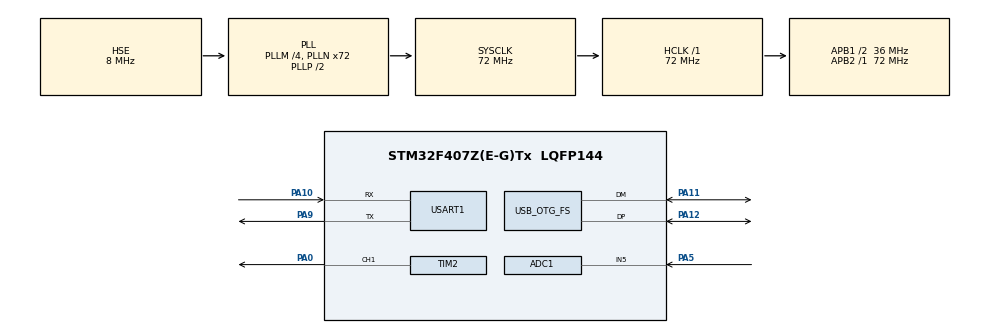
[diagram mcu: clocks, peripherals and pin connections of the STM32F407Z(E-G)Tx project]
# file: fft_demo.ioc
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ADC1.Channel-0\#ChannelRegularConversion=ADC_CHANNEL_5
ADC1.DMAContinuousRequests=ENABLE
ADC1.DataAlign=ADC_DATAALIGN_RIGHT
ADC1.ExternalTrigConv=ADC_EXTERNALTRIGCONV_T3_TRGO
ADC1.InjNumberOfConversion=0
ADC1.NbrOfConversion=1
ADC1.NbrOfConversionFlag=1
ADC1.Rank-0\#ChannelRegularConversion=1
ADC1.SamplingTime-0\#ChannelRegularConversion=ADC_SAMPLETIME_84CYCLES
ADC1.master=1
Dma.ADC1.0.Direction=DMA_PERIPH_TO_MEMORY
Dma.ADC1.0.FIFOMode=DMA_FIFOMODE_DISABLE
Dma.ADC1.0.Instance=DMA2_Stream0
Dma.ADC1.0.MemDataAlignment=DMA_MDATAALIGN_HALFWORD
Dma.ADC1.0.MemInc=DMA_MINC_ENABLE
Dma.ADC1.0.Mode=DMA_NORMAL
Dma.ADC1.0.PeriphDataAlignment=DMA_PDATAALIGN_HALFWORD
Dma.ADC1.0.PeriphInc=DMA_PINC_DISABLE
Dma.ADC1.0.Priority=DMA_PRIORITY_VERY_HIGH
Dma.Request0=ADC1
Mcu.Family=STM32F4
Mcu.Name=STM32F407Z(E-G)Tx
Mcu.Package=LQFP144
NVIC.DMA2_Stream0_IRQn=true\:0\:0\:false\:false\:true\:false\:true\:true
NVIC.OTG_FS_IRQn=true\:0\:0\:false\:false\:true\:false\:true\:true
NVIC.PriorityGroup=NVIC_PRIORITYGROUP_4
NVIC.TIM6_DAC_IRQn=true\:15\:0\:false\:false\:true\:false\:true\:true
NVIC.TimeBase=TIM6_DAC_IRQn
NVIC.TimeBaseIP=TIM6
PA0-WKUP.Signal=S_TIM2_CH1_ETR
PA10.Mode=Asynchronous
PA10.Signal=USART1_RX
PA11.Mode=Device_Only
PA11.Signal=USB_OTG_FS_DM
PA12.Mode=Device_Only
PA12.Signal=USB_OTG_FS_DP
PA13.Mode=Serial_Wire
PA13.Signal=SYS_JTMS-SWDIO
PA14.Mode=Serial_Wire
PA14.Signal=SYS_JTCK-SWCLK
PA5.Signal=ADCx_IN5
PA9.Mode=Asynchronous
PA9.Signal=USART1_TX
PC14-OSC32_IN.Mode=LSE-External-Oscillator
PC14-OSC32_IN.Signal=RCC_OSC32_IN
PC15-OSC32_OUT.Mode=LSE-External-Oscillator
PC15-OSC32_OUT.Signal=RCC_OSC32_OUT
PH0-OSC_IN.Mode=HSE-External-Oscillator
PH0-OSC_IN.Signal=RCC_OSC_IN
PH1-OSC_OUT.Mode=HSE-External-Oscillator
PH1-OSC_OUT.Signal=RCC_OSC_OUT
ProjectManager.HeapSize=0x800
ProjectManager.StackSize=0x400
ProjectManager.TargetToolchain=MDK-ARM V5.32
RCC.48MHZClocksFreq_Value=48000000
RCC.AHBFreq_Value=72000000
RCC.APB1CLKDivider=RCC_HCLK_DIV2
RCC.APB1Freq_Value=36000000
RCC.APB1TimFreq_Value=72000000
RCC.APB2Freq_Value=72000000
RCC.APB2TimFreq_Value=72000000
RCC.CortexFreq_Value=72000000
RCC.HCLKFreq_Value=72000000
RCC.HSE_VALUE=8000000
RCC.HSI_VALUE=16000000
RCC.PLLM=4
RCC.PLLN=72
RCC.PLLQ=3
RCC.SYSCLKFreq_VALUE=72000000
RCC.SYSCLKSource=RCC_SYSCLKSOURCE_PLLCLK
RCC.VCOOutputFreq_Value=144000000
SH.ADCx_IN5.0=ADC1_IN5,IN5
SH.S_TIM2_CH1_ETR.0=TIM2_CH1,PWM Generation1 CH1
STMicroelectronics.X-CUBE-ALGOBUILD.1.3.0.LibraryCcDSPOoLibraryJjDSPOoLibrary=true
TIM2.Channel-PWM\ Generation1\ CH1=TIM_CHANNEL_1
TIM2.Period=1000-1
TIM2.Prescaler=72-1
TIM2.Pulse-PWM\ Generation1\ CH1=500
TIM3.Period=2-1
TIM3.Prescaler=90-1
TIM3.TIM_MasterOutputTrigger=TIM_TRGO_UPDATE
USART1.VirtualMode=VM_ASYNC
USB_DEVICE.CLASS_NAME_FS=CDC
USB_DEVICE.VirtualMode-CDC_FS=Cdc
USB_DEVICE.VirtualModeFS=Cdc_FS
USB_OTG_FS.VirtualMode=Device_Only
VP_STMicroelectronics.X-CUBE-ALGOBUILD_VS_DSPOoLibraryJjLibrary_1.3.0_1.3.0.Mode=DSPOoLibraryJjLibrary
VP_SYS_VS_tim6.Mode=TIM6
VP_TIM2_VS_ClockSourceINT.Mode=Internal
VP_TIM3_VS_ClockSourceINT.Mode=Internal
VP_USB_DEVICE_VS_USB_DEVICE_CDC_FS.Mode=CDC_FS
board=custom

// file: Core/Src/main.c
/* USER CODE BEGIN Header */
/**
  ******************************************************************************
  * @file           : main.c
  * @brief          : Main program body
  ******************************************************************************
  * @attention
  *
  * Copyright (c) 2023 STMicroelectronics.
  * All rights reserved.
  *
  * This software is licensed under terms that can be found in the LICENSE file
  * in the root directory of this software component.
  * If no LICENSE file comes with this software, it is provided AS-IS.
  *
  ******************************************************************************
  */
/* USER CODE END Header */
#include "main.h"
#include "adc.h"
#include "dma.h"
#include "tim.h"
#include "usart.h"
#include "usb_device.h"
#include "gpio.h"

/* USER CODE BEGIN Includes */
#include "arm_math.h"
#include <stdio.h>
#include "bsp.h"

#include "usbd_cdc_if.h"
/* USER CODE END Includes */

/* USER CODE BEGIN PV */
app_fft_t ftt_test;
/* USER CODE END PV */

void SystemClock_Config(void);

int main(void)
{

  /* MCU Configuration--------------------------------------------------------*/

  /* Reset of all peripherals, Initializes the Flash interface and the Systick. */
  HAL_Init();

  /* Configure the system clock */
  SystemClock_Config();

  /* Initialize all configured peripherals */
  MX_GPIO_Init();
  MX_DMA_Init();
  MX_ADC1_Init();
  MX_TIM3_Init();
  MX_TIM2_Init();
  MX_USART1_UART_Init();
  MX_USB_DEVICE_Init();
  /* USER CODE BEGIN 2 */
  App_FFT_Init(&ftt_test, b_adc_buf);

	HAL_TIM_Base_Start(&htim3);
  HAL_TIM_PWM_Start(&htim2,TIM_CHANNEL_1);

  printf("Get RMS and K! r\n");

	// Test arm_math library
  printf("Test arm_math library \r\n data = %lf \r\n", arm_sin_f32(3.1415926 / 6));

  HAL_ADC_Start_DMA(&hadc1,(uint32_t *)b_adc_buf,1024);
  /* USER CODE END 2 */

  /* Infinite loop */
  /* USER CODE BEGIN WHILE */
  while (1)
  {
		HAL_ADC_Start_DMA(&hadc1,(uint32_t *)b_adc_buf,1024);
    HAL_Delay(500);
    /* USER CODE END WHILE */

  }
}

void SystemClock_Config(void)
{
  RCC_OscInitTypeDef RCC_OscInitStruct = {0};
  RCC_ClkInitTypeDef RCC_ClkInitStruct = {0};

  /** Configure the main internal regulator output voltage
  */
  __HAL_RCC_PWR_CLK_ENABLE();
  __HAL_PWR_VOLTAGESCALING_CONFIG(PWR_REGULATOR_VOLTAGE_SCALE1);

  /** Initializes the RCC Oscillators according to the specified parameters
  * in the RCC_OscInitTypeDef structure.
  */
  RCC_OscInitStruct.OscillatorType = RCC_OSCILLATORTYPE_HSE;
  RCC_OscInitStruct.HSEState = RCC_HSE_ON;
  RCC_OscInitStruct.PLL.PLLState = RCC_PLL_ON;
  RCC_OscInitStruct.PLL.PLLSource = RCC_PLLSOURCE_HSE;
  RCC_OscInitStruct.PLL.PLLM = 4;
  RCC_OscInitStruct.PLL.PLLN = 72;
  RCC_OscInitStruct.PLL.PLLP = RCC_PLLP_DIV2;
  RCC_OscInitStruct.PLL.PLLQ = 3;
  if (HAL_RCC_OscConfig(&RCC_OscInitStruct) != HAL_OK)
  {
    Error_Handler();
  }

  /** Initializes the CPU, AHB and APB buses clocks
  */
  RCC_ClkInitStruct.ClockType = RCC_CLOCKTYPE_HCLK|RCC_CLOCKTYPE_SYSCLK
                              |RCC_CLOCKTYPE_PCLK1|RCC_CLOCKTYPE_PCLK2;
  RCC_ClkInitStruct.SYSCLKSource = RCC_SYSCLKSOURCE_PLLCLK;
  RCC_ClkInitStruct.AHBCLKDivider = RCC_SYSCLK_DIV1;
  RCC_ClkInitStruct.APB1CLKDivider = RCC_HCLK_DIV2;
  RCC_ClkInitStruct.APB2CLKDivider = RCC_HCLK_DIV1;

  if (HAL_RCC_ClockConfig(&RCC_ClkInitStruct, FLASH_LATENCY_2) != HAL_OK)
  {
    Error_Handler();
  }
}

void HAL_TIM_PeriodElapsedCallback(TIM_HandleTypeDef *htim)
{
  if (htim->Instance == TIM6) {
    HAL_IncTick();
  }
}

void Error_Handler(void)
{
  __disable_irq();
  while (1)
  {
  }
}
